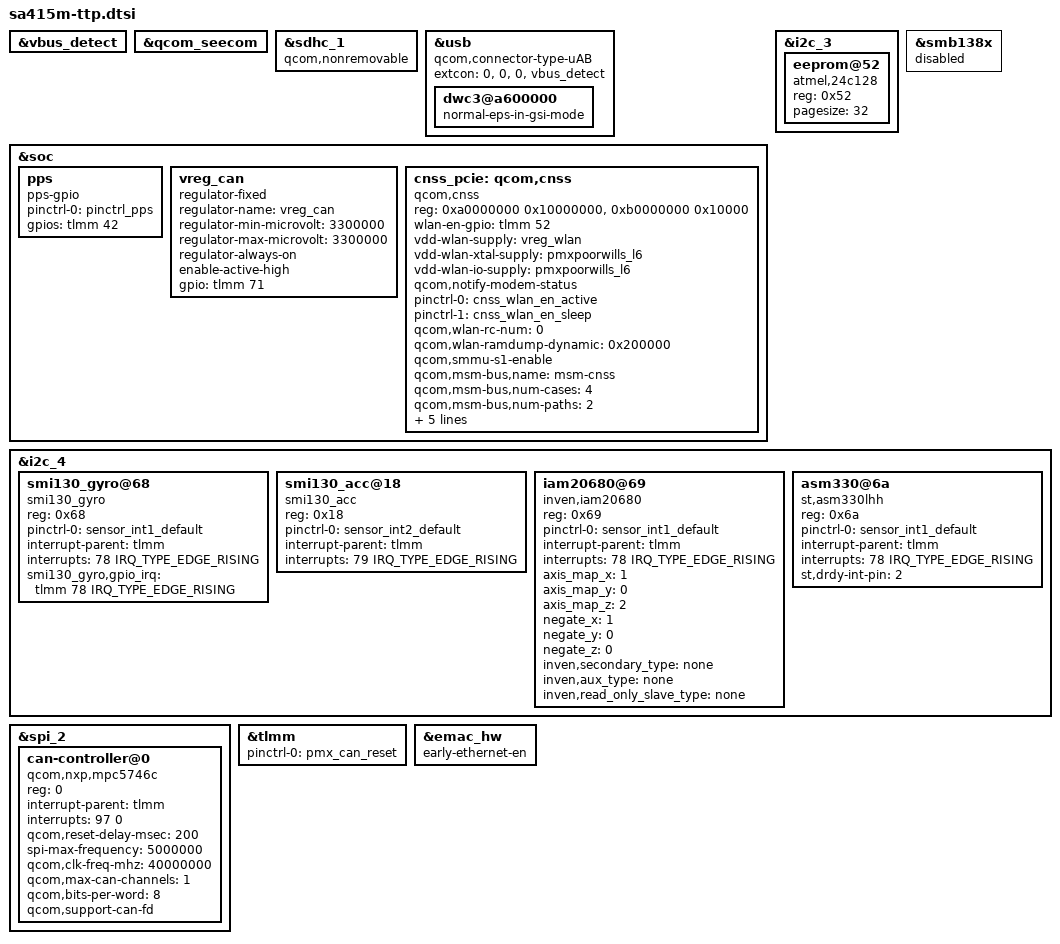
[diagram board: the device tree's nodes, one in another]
/* Copyright (c) 2018-2019, The Linux Foundation. All rights reserved.
 *
 * This program is free software; you can redistribute it and/or modify
 * it under the terms of the GNU General Public License version 2 and
 * only version 2 as published by the Free Software Foundation.
 *
 * This program is distributed in the hope that it will be useful,
 * but WITHOUT ANY WARRANTY; without even the implied warranty of
 * MERCHANTABILITY or FITNESS FOR A PARTICULAR PURPOSE.  See the
 * GNU General Public License for more details.
 */

#include "sdxpoorwills-mtp.dtsi"

&vbus_detect {
	status = "okay";
};

&qcom_seecom {
	status = "okay";
};

&sdhc_1 {
	qcom,nonremovable;
};

&usb {
	status = "okay";
	qcom,connector-type-uAB;
	extcon = <0>, <0>, <0>, <&vbus_detect>;
	dwc3@a600000 {
		normal-eps-in-gsi-mode;
	};
};

&soc {
	pps {
		compatible = "pps-gpio";
		pinctrl-names = "default";
		pinctrl-0 = <&pinctrl_pps>;
		gpios = <&tlmm 42 GPIO_ACTIVE_HIGH>;
		status = "okay";
	};

	vreg_can: vreg_can {
		compatible = "regulator-fixed";
		regulator-name = "vreg_can";
		regulator-min-microvolt = <3300000>;
		regulator-max-microvolt = <3300000>;
		regulator-always-on;
		enable-active-high;
		gpio = <&tlmm 71 GPIO_ACTIVE_HIGH>;
	};
	cnss_pcie: qcom,cnss {
		compatible = "qcom,cnss";
		reg = <0xa0000000 0x10000000>,
		      <0xb0000000 0x10000>;
		reg-names = "smmu_iova_base", "smmu_iova_ipa";

		wlan-en-gpio = <&tlmm 52 0>;
		vdd-wlan-supply = <&vreg_wlan>;
		vdd-wlan-xtal-supply = <&pmxpoorwills_l6>;
		vdd-wlan-io-supply = <&pmxpoorwills_l6>;
		qcom,notify-modem-status;
		pinctrl-names = "wlan_en_active", "wlan_en_sleep";
		pinctrl-0 = <&cnss_wlan_en_active>;
		pinctrl-1 = <&cnss_wlan_en_sleep>;
		qcom,wlan-rc-num = <0>;
		qcom,wlan-ramdump-dynamic = <0x200000>;
		qcom,smmu-s1-enable;
		qcom,msm-bus,name = "msm-cnss";
		qcom,msm-bus,num-cases = <4>;
		qcom,msm-bus,num-paths = <2>;
		qcom,msm-bus,vectors-KBps =
				<45 512 0 0>, <1 512 0 0>,
				/* Upto 200 Mbps */
				<45 512 41421 655360>, <1 512 41421 655360>,
				/* Upto 400 Mbps */
				<45 512 98572 655360>, <1 512 98572 1600000>,
				/* Upto 800 Mbps */
				<45 512 207108 1146880>, <1 512 207108 3124992>;

	};
};

&i2c_3 {
	eeprom@52 {
		compatible = "atmel,24c128";
		reg = <0x52>;
		pagesize = <32>;
	};
};

&smb138x {
	status = "disabled";
};

&i2c_4 {
	status = "okay";

	smi130_gyro@68 {
		compatible = "smi130_gyro";
		reg = <0x68>;
		pinctrl-names = "default";
		pinctrl-0 = <&sensor_int1_default>;
		interrupt-parent = <&tlmm>;
		interrupts = <78 IRQ_TYPE_EDGE_RISING>;
		smi130_gyro,gpio_irq = <&tlmm 78 IRQ_TYPE_EDGE_RISING>;
	};

	smi130_acc@18 {
		compatible = "smi130_acc";
		reg = <0x18>;
		pinctrl-names = "default";
		pinctrl-0 = <&sensor_int2_default>;
		interrupt-parent = <&tlmm>;
		interrupts = <79 IRQ_TYPE_EDGE_RISING>;
	};

	iam20680@69 {
	       compatible = "inven,iam20680";
	       reg = <0x69>;
	       pinctrl-names = "default";
	       pinctrl-0 = <&sensor_int1_default>;
	       interrupt-parent = <&tlmm>;
	       interrupts = <78 IRQ_TYPE_EDGE_RISING>;
	       axis_map_x = <1>;
	       axis_map_y = <0>;
	       axis_map_z = <2>;
	       negate_x = <1>;
	       negate_y = <0>;
	       negate_z = <0>;
	       inven,secondary_type = "none";
	       inven,aux_type = "none";
	       inven,read_only_slave_type = "none";
	};

	asm330@6a {
	       compatible = "st,asm330lhh";
	       reg = <0x6a>;
	       pinctrl-names = "default";
	       pinctrl-0 = <&sensor_int1_default>;
	       interrupt-parent = <&tlmm>;
	       interrupts = <78 IRQ_TYPE_EDGE_RISING>;
	       st,drdy-int-pin= <2>;
	};
};

&spi_2 {
	status = "okay";

	can-controller@0 {
		compatible = "qcom,nxp,mpc5746c";
		reg = <0>;
		interrupt-parent = <&tlmm>;
		interrupts = <97 0>;
		qcom,reset-delay-msec = <200>;
		spi-max-frequency = <5000000>;
		qcom,clk-freq-mhz = <40000000>;
		qcom,max-can-channels = <1>;
		qcom,bits-per-word = <8>;
		qcom,support-can-fd;
	};
};

&tlmm {
	/* Set these up as hogs */
	pinctrl-names = "default";
	pinctrl-0 = <&pmx_can_reset>;
};

&emac_hw {
	early-ethernet-en;
};
